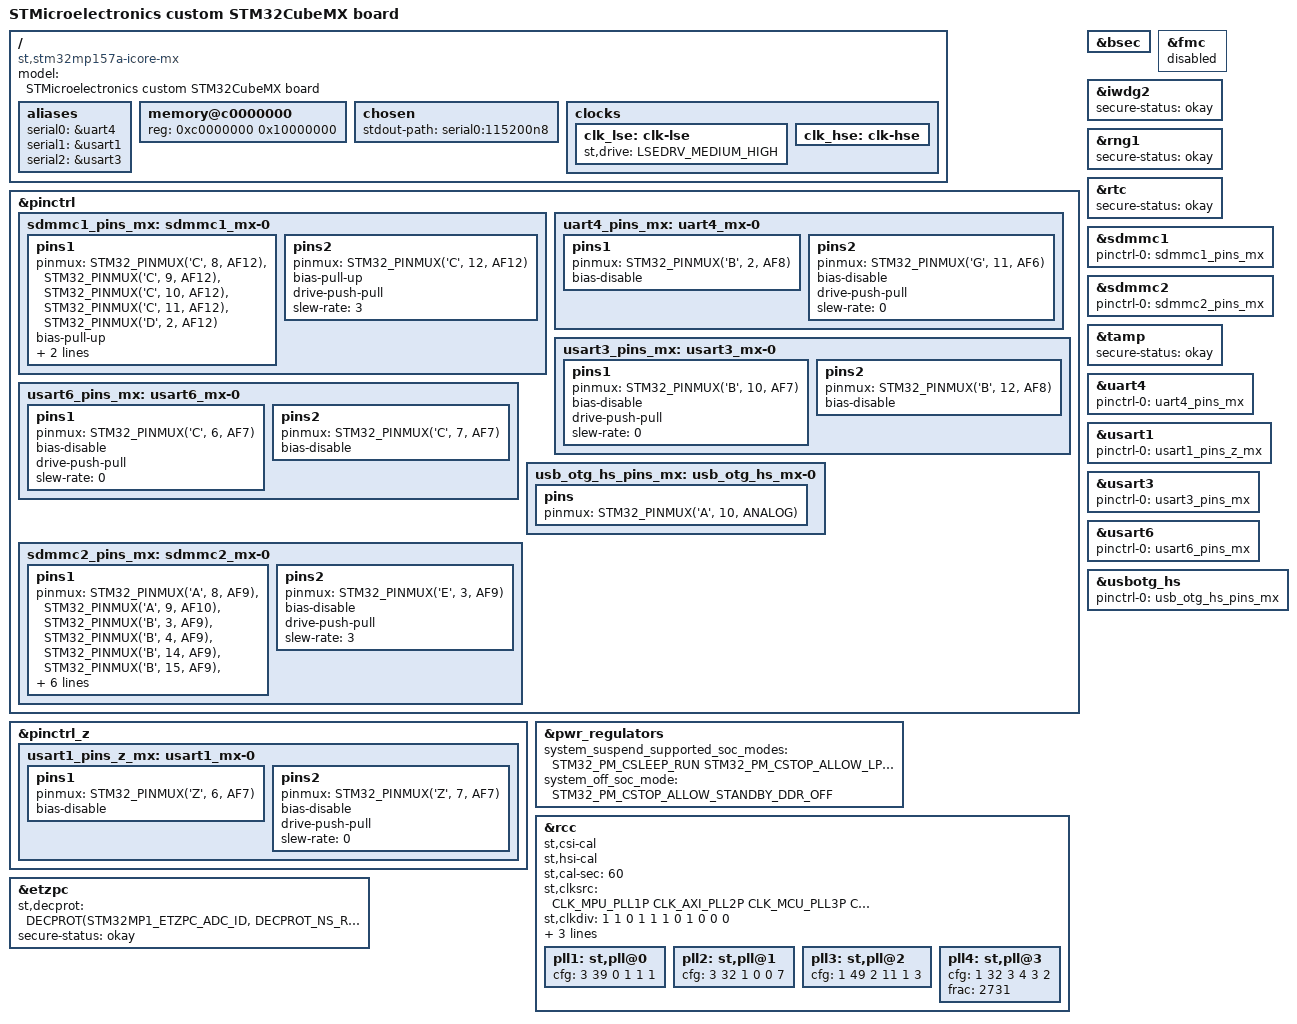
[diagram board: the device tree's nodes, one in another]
/* SPDX-License-Identifier: (GPL-2.0+ OR BSD-3-Clause) */
/*
* Copyright (C) STMicroelectronics 2020 - All Rights Reserved
* Author: STM32CubeMX code generation for STMicroelectronics.
*/

/* For more information on Device Tree configuration, please refer to
* https://wiki.st.com/stm32mpu/wiki/Category:Device_tree_configuration
*/

/dts-v1/;
#include <dt-bindings/pinctrl/stm32-pinfunc.h>
#include <dt-bindings/clock/stm32mp1-clksrc.h>
#include <dt-bindings/soc/st,stm32-etzpc.h>
#include "stm32mp15-mx.dtsi"
#include <dt-bindings/power/stm32mp1-power.h>
#include "stm32mp157.dtsi"
#include "stm32mp15xa.dtsi"
#include "stm32mp15xxaa-pinctrl.dtsi"
#include "stm32mp15-ddr.dtsi"

/* STM32MP157A
 * 256 DDR
 * 600MHz
 */

/ {
model = "STMicroelectronics custom STM32CubeMX board";
compatible = "st,stm32mp157a-icore-mx", "st,stm32mp157";

/* USER CODE BEGIN root */

aliases {
	serial0 = &uart4;
	serial1 = &usart1;
	serial2 = &usart3;
};


memory@c0000000 {
	device_type = "memory";
	reg = <0xc0000000 0x10000000>;
};

chosen {
	stdout-path = "serial0:115200n8";
};

clocks {
	clk_lse: clk-lse {
		st,drive = < LSEDRV_MEDIUM_HIGH >;
	};

	clk_hse: clk-hse {
	};
};

}; /*root*/

&pinctrl {
	/*rtc_pins_mx: rtc_mx-0 {
		pins {
			pinmux = <STM32_PINMUX('I', 8, ANALOG)>; // RTC_LSCO
		};
	};*/

	sdmmc1_pins_mx: sdmmc1_mx-0 {
		pins1 {
			pinmux = <STM32_PINMUX('C', 8, AF12)>, /* SDMMC1_D0 */
					<STM32_PINMUX('C', 9, AF12)>, /* SDMMC1_D1 */
					<STM32_PINMUX('C', 10, AF12)>, /* SDMMC1_D2 */
					<STM32_PINMUX('C', 11, AF12)>, /* SDMMC1_D3 */
					<STM32_PINMUX('D', 2, AF12)>; /* SDMMC1_CMD */
			bias-pull-up;
			drive-push-pull;
			slew-rate = <3>;
		};
		pins2 {
			pinmux = <STM32_PINMUX('C', 12, AF12)>; /* SDMMC1_CK */
			bias-pull-up;
			drive-push-pull;
			slew-rate = <3>;
		};
	};

	uart4_pins_mx: uart4_mx-0 {
		pins1 {
			pinmux = <STM32_PINMUX('B', 2, AF8)>; /* UART4_RX */
			bias-disable;
		};
		pins2 {
			pinmux = <STM32_PINMUX('G', 11, AF6)>; /* UART4_TX */
			bias-disable;
			drive-push-pull;
			slew-rate = <0>;
		};
	};

	usart3_pins_mx: usart3_mx-0 {
		pins1 {
			pinmux = <STM32_PINMUX('B', 10, AF7)>; /* USART3_TX */
			bias-disable;
			drive-push-pull;
			slew-rate = <0>;
		};
		pins2 {
			pinmux = <STM32_PINMUX('B', 12, AF8)>; /* USART3_RX */
			bias-disable;
		};
	};

	usart6_pins_mx: usart6_mx-0 {
		pins1 {
			pinmux = <STM32_PINMUX('C', 6, AF7)>; /* USART6_TX */
			bias-disable;
			drive-push-pull;
			slew-rate = <0>;
		};
		pins2 {
			pinmux = <STM32_PINMUX('C', 7, AF7)>; /* USART6_RX */
			bias-disable;
		};
	};

	usb_otg_hs_pins_mx: usb_otg_hs_mx-0 {
		pins {
			pinmux = <STM32_PINMUX('A', 10, ANALOG)>; /* USB_OTG_HS_ID */
		};
	};

	sdmmc2_pins_mx: sdmmc2_mx-0 {
		pins1 {
			pinmux = <STM32_PINMUX('A', 8, AF9)>, /* SDMMC2_D4 */
						<STM32_PINMUX('A', 9, AF10)>, /* SDMMC2_D5 */
						<STM32_PINMUX('B', 3, AF9)>, /* SDMMC2_D2 */
						<STM32_PINMUX('B', 4, AF9)>, /* SDMMC2_D3 */
						<STM32_PINMUX('B', 14, AF9)>, /* SDMMC2_D0 */
						<STM32_PINMUX('B', 15, AF9)>, /* SDMMC2_D1 */
						<STM32_PINMUX('D', 3, AF9)>, /* SDMMC2_D7 */
						<STM32_PINMUX('E', 5, AF9)>, /* SDMMC2_D6 */
						<STM32_PINMUX('G', 6, AF10)>; /* SDMMC2_CMD */
			bias-disable;
			drive-push-pull;
			slew-rate = <1>;
		};
		pins2 {
			pinmux = <STM32_PINMUX('E', 3, AF9)>; /* SDMMC2_CK */
			bias-disable;
			drive-push-pull;
			slew-rate = <3>;
		};
	};
};

&pinctrl_z {
	usart1_pins_z_mx: usart1_mx-0 {
		pins1 {
			pinmux = <STM32_PINMUX('Z', 6, AF7)>; /* USART1_RX */
			bias-disable;
		};
		pins2 {
			pinmux = <STM32_PINMUX('Z', 7, AF7)>; /* USART1_TX */
			bias-disable;
			drive-push-pull;
			slew-rate = <0>;
		};
	};
};

&pwr_regulators {
	system_suspend_supported_soc_modes = <
		STM32_PM_CSLEEP_RUN
		STM32_PM_CSTOP_ALLOW_LP_STOP
		STM32_PM_CSTOP_ALLOW_LPLV_STOP
		STM32_PM_CSTOP_ALLOW_STANDBY_DDR_SR
	>;
	system_off_soc_mode = <STM32_PM_CSTOP_ALLOW_STANDBY_DDR_OFF>;
};

&bsec{
	status = "okay";
};

&rcc {
	st,csi-cal;
	st,hsi-cal;
	st,cal-sec = <60>;
	st,clksrc = <
		CLK_MPU_PLL1P
		CLK_AXI_PLL2P
		CLK_MCU_PLL3P
		CLK_PLL12_HSI
		CLK_PLL3_HSE
		CLK_PLL4_HSE
		CLK_RTC_LSE
		CLK_MCO1_DISABLED
		CLK_MCO2_DISABLED
	>;
	st,clkdiv = <
		1 		/*MPU*/
		1 		/*AXI*/
		0 		/*MCU*/
		1 		/*APB1*/
		1 		/*APB2*/
		1 		/*APB3*/
		0 		/*APB4*/
		1 		/*APB5*/
		0 		/*RTC*/
		0 		/*MCO1*/
		0 		/*MCO2*/
	>;
	st,pkcs = <
		CLK_CKPER_DISABLED
		CLK_FMC_ACLK
		CLK_ETH_PLL3Q
		CLK_SDMMC12_HSI
		CLK_DSI_DSIPLL
		CLK_STGEN_HSI
		CLK_USBPHY_HSE
		CLK_SPI2S1_DISABLED
		CLK_SPI2S23_DISABLED
		CLK_SPI45_DISABLED
		CLK_SPI6_DISABLED
		CLK_I2C46_PCLK5
		CLK_SDMMC3_DISABLED
		CLK_USBO_USBPHY
		CLK_ADC_PLL4R
		CLK_CEC_DISABLED
		CLK_I2C12_PCLK1
		CLK_I2C35_DISABLED
		CLK_UART1_HSI
		CLK_UART24_HSE
		CLK_UART35_PCLK1
		CLK_UART6_DISABLED
		CLK_UART78_DISABLED
		CLK_SPDIF_DISABLED
		CLK_FDCAN_HSE
    CLK_SAI1_PLL4Q
    CLK_SAI2_PLL3Q
		CLK_SAI3_DISABLED
		CLK_SAI4_DISABLED
		CLK_LPTIM1_DISABLED
		CLK_LPTIM23_DISABLED
		CLK_LPTIM45_DISABLED
	>;
    pll1:st,pll@0 {
        cfg = < 3 39 0 1 1 1>;
    };
    pll2:st,pll@1 {
        cfg = < 3 32 1 0 0 7>;
    };
    pll3:st,pll@2 {
        cfg = < 1 49 2 11 1 3>;
    };
    pll4:st,pll@3 {
        cfg = < 1 32 3 4 3 2>;
        frac = < 2731 >;
    };
};

&etzpc{
	st,decprot = <
	/*"Non Secured" peripherals*/
	DECPROT(STM32MP1_ETZPC_ADC_ID, DECPROT_NS_RW, DECPROT_UNLOCK)
	DECPROT(STM32MP1_ETZPC_DMA1_ID, DECPROT_NS_RW, DECPROT_UNLOCK)
	DECPROT(STM32MP1_ETZPC_DMAMUX_ID, DECPROT_NS_RW, DECPROT_UNLOCK)
	DECPROT(STM32MP1_ETZPC_ETH_ID, DECPROT_NS_RW, DECPROT_UNLOCK)
	DECPROT(STM32MP1_ETZPC_TT_FDCAN_ID, DECPROT_NS_RW, DECPROT_UNLOCK)
	DECPROT(STM32MP1_ETZPC_I2C2_ID, DECPROT_NS_RW, DECPROT_UNLOCK)
	DECPROT(STM32MP1_ETZPC_I2C4_ID, DECPROT_NS_RW, DECPROT_UNLOCK)
	DECPROT(STM32MP1_ETZPC_RNG1_ID, DECPROT_NS_RW, DECPROT_UNLOCK)
	DECPROT(STM32MP1_ETZPC_SAI2_ID, DECPROT_NS_RW, DECPROT_UNLOCK)
	DECPROT(STM32MP1_ETZPC_TIM12_ID, DECPROT_NS_RW, DECPROT_UNLOCK)
	DECPROT(STM32MP1_ETZPC_UART4_ID, DECPROT_NS_RW, DECPROT_UNLOCK)
	DECPROT(STM32MP1_ETZPC_UART7_ID, DECPROT_NS_RW, DECPROT_UNLOCK)
	DECPROT(STM32MP1_ETZPC_UART8_ID, DECPROT_NS_RW, DECPROT_UNLOCK)
	DECPROT(STM32MP1_ETZPC_USART1_ID, DECPROT_NS_RW, DECPROT_UNLOCK)
	DECPROT(STM32MP1_ETZPC_USART3_ID, DECPROT_NS_RW, DECPROT_UNLOCK)
	DECPROT(STM32MP1_ETZPC_USART6_ID, DECPROT_NS_RW, DECPROT_UNLOCK)
	DECPROT(STM32MP1_ETZPC_OTG_ID, DECPROT_NS_RW, DECPROT_UNLOCK)
	/*"Secured" peripherals*/
	DECPROT(STM32MP1_ETZPC_DDRCTRL_ID, DECPROT_S_RW, DECPROT_UNLOCK)
	DECPROT(STM32MP1_ETZPC_DDRPHYC_ID, DECPROT_S_RW, DECPROT_UNLOCK)
	DECPROT(STM32MP1_ETZPC_STGENC_ID, DECPROT_S_RW, DECPROT_UNLOCK)
	/*"Mcu Isolation" peripherals*/
	DECPROT(STM32MP1_ETZPC_DMA2_ID, DECPROT_MCU_ISOLATION, DECPROT_UNLOCK)

	/*Restriction: following IDs are not managed  - please to use User-Section if needed:
		STM32MP1_ETZPC_SRAMx_ID, STM32MP1_ETZPC_RETRAM_ID, STM32MP1_ETZPC_BKPSRAM_ID*/

	/* USER CODE BEGIN etzpc_decprot */
		/*STM32CubeMX generates a basic and standard configuration for ETZPC.
		Additional device configurations can be added here if needed.
		"etzpc" node could be also overloaded in "addons" User-Section.*/
	/* USER CODE END etzpc_decprot */
	>;

	secure-status = "okay";
};

&fmc{
	status = "disabled";
};

&iwdg2{
	status = "okay";
	secure-status = "okay";
};

&rcc{
	status = "okay";
	secure-status = "okay";
};

&rng1{
	status = "okay";
	secure-status = "okay";
};

&rtc{
	status = "okay";
	secure-status = "okay";
};

&sdmmc1 {
	pinctrl-names = "default";
	pinctrl-0 = <&sdmmc1_pins_mx>;
	status = "okay";
};

&sdmmc2{
	pinctrl-names = "default";
	pinctrl-0 = <&sdmmc2_pins_mx>;
	status = "okay";
};

&tamp{
	status = "okay";
	secure-status = "okay";
};

&uart4{
	pinctrl-names = "default";
	pinctrl-0 = <&uart4_pins_mx>;
	status = "okay";
};

&usart1{
	pinctrl-names = "default";
	pinctrl-0 = <&usart1_pins_z_mx>;
	status = "okay";
};

&usart3{
	pinctrl-names = "default";
	pinctrl-0 = <&usart3_pins_mx>;
	status = "okay";
};

&usart6{
	pinctrl-names = "default";
	pinctrl-0 = <&usart6_pins_mx>;
	status = "okay";
};

&usbotg_hs{
    pinctrl-names = "default";
    pinctrl-0 = <&usb_otg_hs_pins_mx>;
    status = "okay";
};
